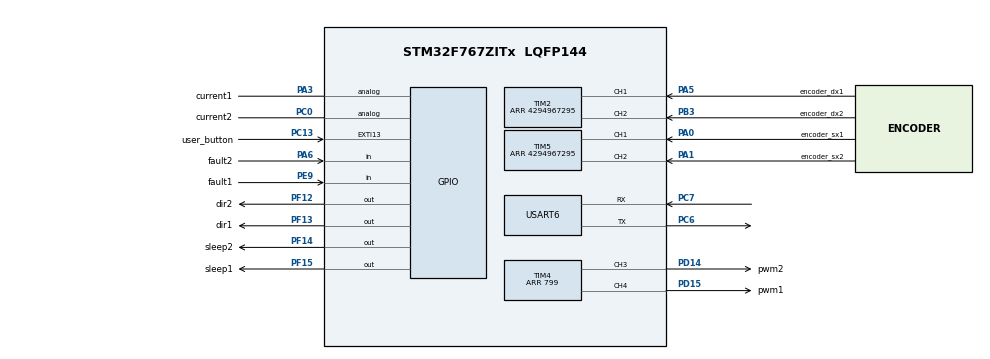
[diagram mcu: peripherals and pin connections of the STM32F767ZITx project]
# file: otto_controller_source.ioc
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Mcu.Family=STM32F7
Mcu.Name=STM32F767ZITx
Mcu.Package=LQFP144
NVIC.EXTI15_10_IRQn=true\:0\:0\:false\:false\:true\:true\:true
NVIC.PriorityGroup=NVIC_PRIORITYGROUP_2
NVIC.TIM3_IRQn=true\:2\:1\:true\:true\:true\:1\:true\:true
NVIC.TIM6_DAC_IRQn=true\:2\:2\:true\:true\:true\:2\:true\:true
NVIC.USART6_IRQn=true\:2\:0\:true\:true\:true\:3\:true\:true
PA0/WKUP.GPIO_Label=encoder_sx1
PA0/WKUP.Signal=S_TIM5_CH1
PA1.GPIO_Label=encoder_sx2
PA1.Signal=S_TIM5_CH2
PA13.Mode=Serial_Wire
PA13.Signal=SYS_JTMS-SWDIO
PA14.Mode=Serial_Wire
PA14.Signal=SYS_JTCK-SWCLK
PA3.GPIO_Label=current1
PA3.Signal=GPIO_Analog
PA5.GPIO_Label=encoder_dx1
PA5.Signal=S_TIM2_CH1_ETR
PA6.GPIO_Label=fault2
PA6.Signal=GPIO_Input
PB3.GPIO_Label=encoder_dx2
PB3.Signal=S_TIM2_CH2
PC0.GPIO_Label=current2
PC0.Signal=GPIO_Analog
PC13.GPIO_Label=user_button
PC13.Signal=GPXTI13
PC6.Mode=Asynchronous
PC6.Signal=USART6_TX
PC7.Mode=Asynchronous
PC7.Signal=USART6_RX
PD14.GPIO_Label=pwm2
PD14.Signal=S_TIM4_CH3
PD15.GPIO_Label=pwm1
PD15.Signal=S_TIM4_CH4
PE9.GPIO_Label=fault1
PE9.Signal=GPIO_Input
PF12.GPIO_Label=dir2
PF12.Signal=GPIO_Output
PF13.GPIO_Label=dir1
PF13.Signal=GPIO_Output
PF14.GPIO_Label=sleep2
PF14.GPIO_ModeDefaultOutputPP=GPIO_MODE_OUTPUT_PP
PF14.GPIO_PuPd=GPIO_PULLUP
PF14.PinState=GPIO_PIN_SET
PF14.Signal=GPIO_Output
PF15.GPIO_Label=sleep1
PF15.GPIO_PuPd=GPIO_PULLUP
PF15.PinState=GPIO_PIN_SET
PF15.Signal=GPIO_Output
ProjectManager.HeapSize=0x200
ProjectManager.StackSize=0x400
ProjectManager.TargetToolchain=STM32CubeIDE
RCC.HSE_VALUE=25000000
RCC.HSI_VALUE=16000000
RCC.LSE_VALUE=32768
RCC.USBFreq_Value=96000000
RCC.VCOOutputFreq_Value=192000000
SH.S_TIM2_CH1_ETR.0=TIM2_CH1,Encoder_Interface
SH.S_TIM2_CH2.0=TIM2_CH2,Encoder_Interface
SH.S_TIM4_CH3.0=TIM4_CH3,PWM Generation3 CH3
SH.S_TIM4_CH4.0=TIM4_CH4,PWM Generation4 CH4
SH.S_TIM5_CH1.0=TIM5_CH1,Encoder_Interface
SH.S_TIM5_CH2.0=TIM5_CH2,Encoder_Interface
TIM2.EncoderMode=TIM_ENCODERMODE_TI12
TIM2.Period=4294967295
TIM3.Period=159
TIM3.Prescaler=999
TIM4.Channel-PWM\ Generation3\ CH3=TIM_CHANNEL_3
TIM4.Channel-PWM\ Generation4\ CH4=TIM_CHANNEL_4
TIM4.Period=799
TIM5.EncoderMode=TIM_ENCODERMODE_TI12
TIM5.Period=4294967295
TIM6.Period=799
TIM6.Prescaler=9999
USART6.Parity=PARITY_ODD
USART6.VirtualMode-Asynchronous=VM_ASYNC
USART6.WordLength=WORDLENGTH_9B
VP_TIM3_VS_ClockSourceINT.Mode=Internal
VP_TIM4_VS_ClockSourceINT.Mode=Internal
VP_TIM6_VS_ClockSourceINT.Mode=Enable_Timer
board=custom

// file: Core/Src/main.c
/* USER CODE BEGIN Header */
/**
 ******************************************************************************
 * @file           : main.c
 * @brief          : Main program body
 ******************************************************************************
 * @attention
 *
 * <h2><center>&copy; Copyright (c) 2019 STMicroelectronics.
 * All rights reserved.</center></h2>
 *
 * This software component is licensed by ST under BSD 3-Clause license,
 * the "License"; You may not use this file except in compliance with the
 * License. You may obtain a copy of the License at:
 *                        opensource.org/licenses/BSD-3-Clause
 *
 ******************************************************************************
 */
/* USER CODE END Header */

#include "main.h"

/* USER CODE BEGIN Includes */

#include <encoder.h>
#include <odometry_calc.h>

/* USER CODE END Includes */

TIM_HandleTypeDef htim2;
TIM_HandleTypeDef htim3;
TIM_HandleTypeDef htim4;
TIM_HandleTypeDef htim5;
TIM_HandleTypeDef htim6;

UART_HandleTypeDef huart6;
DMA_HandleTypeDef hdma_usart6_rx;
DMA_HandleTypeDef hdma_usart6_tx;

/* USER CODE BEGIN PV */

//Odometry
Encoder left_encoder = Encoder(&htim5);
Encoder right_encoder = Encoder(&htim2);
OdometryCalc odom = OdometryCalc(left_encoder, right_encoder);
//test stuff

float delta_r = 0;
float delta_l = 0;
float velocity_l = 0;
float velocity_r = 0;

/* USER CODE END PV */

void SystemClock_Config(void);
static void MX_GPIO_Init(void);
static void MX_DMA_Init(void);
static void MX_TIM2_Init(void);
static void MX_TIM3_Init(void);
static void MX_TIM4_Init(void);
static void MX_TIM5_Init(void);
static void MX_USART6_UART_Init(void);
static void MX_TIM6_Init(void);

int main(void)
{

  /* MCU Configuration--------------------------------------------------------*/

  /* Reset of all peripherals, Initializes the Flash interface and the Systick. */
  HAL_Init();

  /* Configure the system clock */
  SystemClock_Config();

  /* Initialize all configured peripherals */
  MX_GPIO_Init();
  MX_DMA_Init();
  MX_TIM2_Init();
  MX_TIM3_Init();
  MX_TIM4_Init();
  MX_TIM5_Init();
  MX_USART6_UART_Init();
  MX_TIM6_Init();
  /* USER CODE BEGIN 2 */

	left_encoder.Setup();
	right_encoder.Setup();

//	HAL_TIM_Base_Start_IT(&htim3);

  /* USER CODE END 2 */

  /* Infinite loop */
	while (1) {

	}
}

void SystemClock_Config(void)
{
  RCC_OscInitTypeDef RCC_OscInitStruct = {0};
  RCC_ClkInitTypeDef RCC_ClkInitStruct = {0};
  RCC_PeriphCLKInitTypeDef PeriphClkInitStruct = {0};

  /** Configure the main internal regulator output voltage
  */
  __HAL_RCC_PWR_CLK_ENABLE();
  __HAL_PWR_VOLTAGESCALING_CONFIG(PWR_REGULATOR_VOLTAGE_SCALE3);
  /** Initializes the CPU, AHB and APB busses clocks
  */
  RCC_OscInitStruct.OscillatorType = RCC_OSCILLATORTYPE_HSI;
  RCC_OscInitStruct.HSIState = RCC_HSI_ON;
  RCC_OscInitStruct.HSICalibrationValue = RCC_HSICALIBRATION_DEFAULT;
  RCC_OscInitStruct.PLL.PLLState = RCC_PLL_NONE;
  if (HAL_RCC_OscConfig(&RCC_OscInitStruct) != HAL_OK)
  {
    Error_Handler();
  }
  /** Initializes the CPU, AHB and APB busses clocks
  */
  RCC_ClkInitStruct.ClockType = RCC_CLOCKTYPE_HCLK|RCC_CLOCKTYPE_SYSCLK
                              |RCC_CLOCKTYPE_PCLK1|RCC_CLOCKTYPE_PCLK2;
  RCC_ClkInitStruct.SYSCLKSource = RCC_SYSCLKSOURCE_HSI;
  RCC_ClkInitStruct.AHBCLKDivider = RCC_SYSCLK_DIV1;
  RCC_ClkInitStruct.APB1CLKDivider = RCC_HCLK_DIV1;
  RCC_ClkInitStruct.APB2CLKDivider = RCC_HCLK_DIV1;

  if (HAL_RCC_ClockConfig(&RCC_ClkInitStruct, FLASH_LATENCY_0) != HAL_OK)
  {
    Error_Handler();
  }
  PeriphClkInitStruct.PeriphClockSelection = RCC_PERIPHCLK_USART6;
  PeriphClkInitStruct.Usart6ClockSelection = RCC_USART6CLKSOURCE_PCLK2;
  if (HAL_RCCEx_PeriphCLKConfig(&PeriphClkInitStruct) != HAL_OK)
  {
    Error_Handler();
  }
}

static void MX_TIM2_Init(void)
{

  TIM_Encoder_InitTypeDef sConfig = {0};
  TIM_MasterConfigTypeDef sMasterConfig = {0};

  htim2.Instance = TIM2;
  htim2.Init.Prescaler = 0;
  htim2.Init.CounterMode = TIM_COUNTERMODE_UP;
  htim2.Init.Period = 4294967295;
  htim2.Init.ClockDivision = TIM_CLOCKDIVISION_DIV1;
  htim2.Init.AutoReloadPreload = TIM_AUTORELOAD_PRELOAD_DISABLE;
  sConfig.EncoderMode = TIM_ENCODERMODE_TI12;
  sConfig.IC1Polarity = TIM_ICPOLARITY_RISING;
  sConfig.IC1Selection = TIM_ICSELECTION_DIRECTTI;
  sConfig.IC1Prescaler = TIM_ICPSC_DIV1;
  sConfig.IC1Filter = 0;
  sConfig.IC2Polarity = TIM_ICPOLARITY_RISING;
  sConfig.IC2Selection = TIM_ICSELECTION_DIRECTTI;
  sConfig.IC2Prescaler = TIM_ICPSC_DIV1;
  sConfig.IC2Filter = 0;
  if (HAL_TIM_Encoder_Init(&htim2, &sConfig) != HAL_OK)
  {
    Error_Handler();
  }
  sMasterConfig.MasterOutputTrigger = TIM_TRGO_RESET;
  sMasterConfig.MasterSlaveMode = TIM_MASTERSLAVEMODE_DISABLE;
  if (HAL_TIMEx_MasterConfigSynchronization(&htim2, &sMasterConfig) != HAL_OK)
  {
    Error_Handler();
  }

}

static void MX_TIM3_Init(void)
{

  TIM_ClockConfigTypeDef sClockSourceConfig = {0};
  TIM_MasterConfigTypeDef sMasterConfig = {0};

  htim3.Instance = TIM3;
  htim3.Init.Prescaler = 9999;
  htim3.Init.CounterMode = TIM_COUNTERMODE_UP;
  htim3.Init.Period = 159;
  htim3.Init.ClockDivision = TIM_CLOCKDIVISION_DIV1;
  htim3.Init.AutoReloadPreload = TIM_AUTORELOAD_PRELOAD_DISABLE;
  if (HAL_TIM_Base_Init(&htim3) != HAL_OK)
  {
    Error_Handler();
  }
  sClockSourceConfig.ClockSource = TIM_CLOCKSOURCE_INTERNAL;
  if (HAL_TIM_ConfigClockSource(&htim3, &sClockSourceConfig) != HAL_OK)
  {
    Error_Handler();
  }
  sMasterConfig.MasterOutputTrigger = TIM_TRGO_RESET;
  sMasterConfig.MasterSlaveMode = TIM_MASTERSLAVEMODE_DISABLE;
  if (HAL_TIMEx_MasterConfigSynchronization(&htim3, &sMasterConfig) != HAL_OK)
  {
    Error_Handler();
  }

}

static void MX_TIM4_Init(void)
{

  TIM_ClockConfigTypeDef sClockSourceConfig = {0};
  TIM_MasterConfigTypeDef sMasterConfig = {0};
  TIM_OC_InitTypeDef sConfigOC = {0};

  htim4.Instance = TIM4;
  htim4.Init.Prescaler = 0;
  htim4.Init.CounterMode = TIM_COUNTERMODE_UP;
  htim4.Init.Period = 799;
  htim4.Init.ClockDivision = TIM_CLOCKDIVISION_DIV1;
  htim4.Init.AutoReloadPreload = TIM_AUTORELOAD_PRELOAD_DISABLE;
  if (HAL_TIM_Base_Init(&htim4) != HAL_OK)
  {
    Error_Handler();
  }
  sClockSourceConfig.ClockSource = TIM_CLOCKSOURCE_INTERNAL;
  if (HAL_TIM_ConfigClockSource(&htim4, &sClockSourceConfig) != HAL_OK)
  {
    Error_Handler();
  }
  if (HAL_TIM_PWM_Init(&htim4) != HAL_OK)
  {
    Error_Handler();
  }
  sMasterConfig.MasterOutputTrigger = TIM_TRGO_RESET;
  sMasterConfig.MasterSlaveMode = TIM_MASTERSLAVEMODE_DISABLE;
  if (HAL_TIMEx_MasterConfigSynchronization(&htim4, &sMasterConfig) != HAL_OK)
  {
    Error_Handler();
  }
  sConfigOC.OCMode = TIM_OCMODE_PWM1;
  sConfigOC.Pulse = 0;
  sConfigOC.OCPolarity = TIM_OCPOLARITY_HIGH;
  sConfigOC.OCFastMode = TIM_OCFAST_DISABLE;
  if (HAL_TIM_PWM_ConfigChannel(&htim4, &sConfigOC, TIM_CHANNEL_3) != HAL_OK)
  {
    Error_Handler();
  }
  if (HAL_TIM_PWM_ConfigChannel(&htim4, &sConfigOC, TIM_CHANNEL_4) != HAL_OK)
  {
    Error_Handler();
  }
  HAL_TIM_MspPostInit(&htim4);

}

static void MX_TIM5_Init(void)
{

  TIM_Encoder_InitTypeDef sConfig = {0};
  TIM_MasterConfigTypeDef sMasterConfig = {0};

  htim5.Instance = TIM5;
  htim5.Init.Prescaler = 0;
  htim5.Init.CounterMode = TIM_COUNTERMODE_UP;
  htim5.Init.Period = 4294967295;
  htim5.Init.ClockDivision = TIM_CLOCKDIVISION_DIV1;
  htim5.Init.AutoReloadPreload = TIM_AUTORELOAD_PRELOAD_DISABLE;
  sConfig.EncoderMode = TIM_ENCODERMODE_TI12;
  sConfig.IC1Polarity = TIM_ICPOLARITY_RISING;
  sConfig.IC1Selection = TIM_ICSELECTION_DIRECTTI;
  sConfig.IC1Prescaler = TIM_ICPSC_DIV1;
  sConfig.IC1Filter = 0;
  sConfig.IC2Polarity = TIM_ICPOLARITY_RISING;
  sConfig.IC2Selection = TIM_ICSELECTION_DIRECTTI;
  sConfig.IC2Prescaler = TIM_ICPSC_DIV1;
  sConfig.IC2Filter = 0;
  if (HAL_TIM_Encoder_Init(&htim5, &sConfig) != HAL_OK)
  {
    Error_Handler();
  }
  sMasterConfig.MasterOutputTrigger = TIM_TRGO_RESET;
  sMasterConfig.MasterSlaveMode = TIM_MASTERSLAVEMODE_DISABLE;
  if (HAL_TIMEx_MasterConfigSynchronization(&htim5, &sMasterConfig) != HAL_OK)
  {
    Error_Handler();
  }

}

static void MX_TIM6_Init(void)
{

  TIM_MasterConfigTypeDef sMasterConfig = {0};

  htim6.Instance = TIM6;
  htim6.Init.Prescaler = 9999;
  htim6.Init.CounterMode = TIM_COUNTERMODE_UP;
  htim6.Init.Period = 799;
  htim6.Init.AutoReloadPreload = TIM_AUTORELOAD_PRELOAD_DISABLE;
  if (HAL_TIM_Base_Init(&htim6) != HAL_OK)
  {
    Error_Handler();
  }
  sMasterConfig.MasterOutputTrigger = TIM_TRGO_RESET;
  sMasterConfig.MasterSlaveMode = TIM_MASTERSLAVEMODE_DISABLE;
  if (HAL_TIMEx_MasterConfigSynchronization(&htim6, &sMasterConfig) != HAL_OK)
  {
    Error_Handler();
  }

}

static void MX_USART6_UART_Init(void)
{

  huart6.Instance = USART6;
  huart6.Init.BaudRate = 115200;
  huart6.Init.WordLength = UART_WORDLENGTH_8B;
  huart6.Init.StopBits = UART_STOPBITS_1;
  huart6.Init.Parity = UART_PARITY_NONE;
  huart6.Init.Mode = UART_MODE_TX_RX;
  huart6.Init.HwFlowCtl = UART_HWCONTROL_NONE;
  huart6.Init.OverSampling = UART_OVERSAMPLING_16;
  huart6.Init.OneBitSampling = UART_ONE_BIT_SAMPLE_DISABLE;
  huart6.AdvancedInit.AdvFeatureInit = UART_ADVFEATURE_NO_INIT;
  if (HAL_UART_Init(&huart6) != HAL_OK)
  {
    Error_Handler();
  }

}

static void MX_DMA_Init(void)
{

  /* DMA controller clock enable */
  __HAL_RCC_DMA2_CLK_ENABLE();

  /* DMA interrupt init */
  /* DMA2_Stream1_IRQn interrupt configuration */
  HAL_NVIC_SetPriority(DMA2_Stream1_IRQn, 2, 0);
  HAL_NVIC_EnableIRQ(DMA2_Stream1_IRQn);
  /* DMA2_Stream6_IRQn interrupt configuration */
  HAL_NVIC_SetPriority(DMA2_Stream6_IRQn, 2, 0);
  HAL_NVIC_EnableIRQ(DMA2_Stream6_IRQn);

}

static void MX_GPIO_Init(void)
{
  GPIO_InitTypeDef GPIO_InitStruct = {0};

  /* GPIO Ports Clock Enable */
  __HAL_RCC_GPIOC_CLK_ENABLE();
  __HAL_RCC_GPIOA_CLK_ENABLE();
  __HAL_RCC_GPIOF_CLK_ENABLE();
  __HAL_RCC_GPIOE_CLK_ENABLE();
  __HAL_RCC_GPIOD_CLK_ENABLE();
  __HAL_RCC_GPIOB_CLK_ENABLE();

  /*Configure GPIO pin Output Level */
  HAL_GPIO_WritePin(GPIOF, dir2_Pin|dir1_Pin|sleep2_Pin|sleep1_Pin, GPIO_PIN_RESET);

  /*Configure GPIO pin : current2_Pin */
  GPIO_InitStruct.Pin = current2_Pin;
  GPIO_InitStruct.Mode = GPIO_MODE_ANALOG;
  GPIO_InitStruct.Pull = GPIO_NOPULL;
  HAL_GPIO_Init(current2_GPIO_Port, &GPIO_InitStruct);

  /*Configure GPIO pin : current1_Pin */
  GPIO_InitStruct.Pin = current1_Pin;
  GPIO_InitStruct.Mode = GPIO_MODE_ANALOG;
  GPIO_InitStruct.Pull = GPIO_NOPULL;
  HAL_GPIO_Init(current1_GPIO_Port, &GPIO_InitStruct);

  /*Configure GPIO pin : fault2_Pin */
  GPIO_InitStruct.Pin = fault2_Pin;
  GPIO_InitStruct.Mode = GPIO_MODE_INPUT;
  GPIO_InitStruct.Pull = GPIO_NOPULL;
  HAL_GPIO_Init(fault2_GPIO_Port, &GPIO_InitStruct);

  /*Configure GPIO pins : dir2_Pin dir1_Pin sleep2_Pin sleep1_Pin */
  GPIO_InitStruct.Pin = dir2_Pin|dir1_Pin|sleep2_Pin|sleep1_Pin;
  GPIO_InitStruct.Mode = GPIO_MODE_OUTPUT_PP;
  GPIO_InitStruct.Pull = GPIO_NOPULL;
  GPIO_InitStruct.Speed = GPIO_SPEED_FREQ_LOW;
  HAL_GPIO_Init(GPIOF, &GPIO_InitStruct);

  /*Configure GPIO pin : fault1_Pin */
  GPIO_InitStruct.Pin = fault1_Pin;
  GPIO_InitStruct.Mode = GPIO_MODE_INPUT;
  GPIO_InitStruct.Pull = GPIO_NOPULL;
  HAL_GPIO_Init(fault1_GPIO_Port, &GPIO_InitStruct);

}

/* USER CODE BEGIN 4 */
void HAL_TIM_PeriodElapsedCallback(TIM_HandleTypeDef *htim) {
	if (htim->Instance == TIM3) {

	}
}
/* USER CODE END 4 */

void Error_Handler(void)
{
}

/************************ (C) COPYRIGHT STMicroelectronics *****END OF FILE****/
